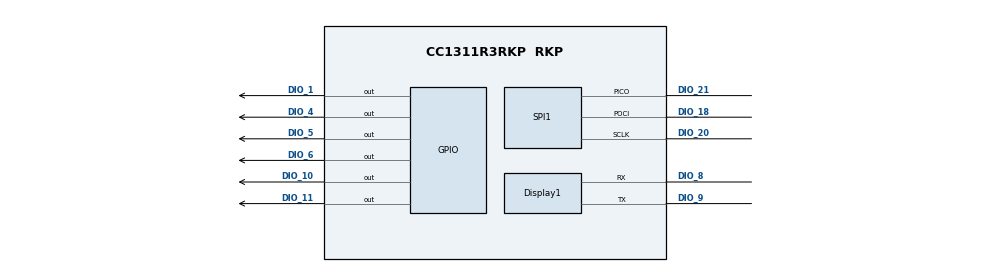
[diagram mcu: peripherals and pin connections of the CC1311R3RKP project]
/**
 * @cliArgs --device "CC1311R3RKP" --part "Default" --package "RKP" --rtos "nortos" --product "simplelink_cc13xx_cc26xx_sdk@8.30.01.01"
 * @versions {"tool":"1.21.1+3772"}
 */

/**
 * Import the modules used in this configuration.
 */
const Display  = scripting.addModule("/ti/display/Display");
const Display1 = Display.addInstance();
const Board    = scripting.addModule("/ti/drivers/Board");
const GPIO     = scripting.addModule("/ti/drivers/GPIO", {}, false);
const GPIO3    = GPIO.addInstance();
const GPIO4    = GPIO.addInstance();
const GPIO5    = GPIO.addInstance();
const GPIO6    = GPIO.addInstance();
const GPIO7    = GPIO.addInstance();
const GPIO8    = GPIO.addInstance();
const NVS      = scripting.addModule("/ti/drivers/NVS");
const NVS1     = NVS.addInstance();
const SPI      = scripting.addModule("/ti/drivers/SPI", {}, false);
const SPI1     = SPI.addInstance();

/**
 * Write custom configuration values to the imported modules.
 */
Display1.$name                   = "CONFIG_DISPLAY_DEBUG";
Display1.baudRate                = 921600;
Display1.uartBufferSize          = 8196;
Display1.uart.$name              = "CONFIG_UART2_DEBUG";
Display1.uart.uart.txPin.$assign = "DIO_9";
Display1.uart.uart.rxPin.$assign = "DIO_8";

Board.generateInitializationFunctions = false;

GPIO3.$name              = "CONFIG_GPIO_EPD_CS";
GPIO3.mode               = "Output";
GPIO3.initialOutputState = "High";
GPIO3.gpioPin.$assign    = "DIO_1";

GPIO4.$name           = "CONFIG_GPIO_EPD_PWR";
GPIO4.mode            = "Output";
GPIO4.gpioPin.$assign = "DIO_4";

GPIO5.$name           = "CONFIG_GPIO_EPD_SDI";
GPIO5.mode            = "Output";
GPIO5.gpioPin.$assign = "DIO_5";

GPIO6.$name           = "CONFIG_GPIO_EPD_CLK";
GPIO6.mode            = "Output";
GPIO6.gpioPin.$assign = "DIO_6";

GPIO7.$name              = "CONFIG_GPIO_EPD_RST";
GPIO7.mode               = "Output";
GPIO7.initialOutputState = "High";
GPIO7.gpioPin.$assign    = "DIO_10";

GPIO8.$name           = "CONFIG_GPIO_EPD_BUSY";
GPIO8.pull            = "Pull Up";
GPIO8.gpioPin.$assign = "DIO_11";

NVS1.nvsType                  = "External";
NVS1.$name                    = "CONFIG_NVS_FLASH";
NVS1.externalFlash.$name      = "ti_drivers_nvs_NVSSPI25X0";
NVS1.externalFlash.regionSize = 0x100000;

const CCFG              = scripting.addModule("/ti/devices/CCFG", {}, false);
CCFG.ccfgTemplate.$name = "ti_devices_CCFG_CCFGCC26XXTemplate0";

const NVSSPI25XDevice                        = scripting.addModule("/ti/drivers/nvs/NVSSPI25XDevice", {}, false);
const NVSSPI25XDevice1                       = NVSSPI25XDevice.addInstance({}, false);
NVSSPI25XDevice1.$name                       = "CONFIG_NVS_SPI_0";
NVS1.externalFlash.spiFlashDevice            = NVSSPI25XDevice1;
NVSSPI25XDevice1.chipSelect.$assign          = "DIO_19";
NVSSPI25XDevice1.chipSelectPinInstance.$name = "CONFIG_GPIO_NVS_FLASH_CS";

NVSSPI25XDevice1.sharedSpiInstance = SPI1;
SPI1.$name                         = "CONFIG_SPI_FLASH";
SPI1.spi.sclkPin.$assign           = "DIO_20";
SPI1.spi.pociPin.$assign           = "DIO_18";
SPI1.spi.picoPin.$assign           = "DIO_21";

/**
 * Pinmux solution for unlocked pins/peripherals. This ensures that minor changes to the automatic solver in a future
 * version of the tool will not impact the pinmux you originally saw.  These lines can be completely deleted in order to
 * re-solve from scratch.
 */
Display1.uart.uart.$suggestSolution    = "UART0";
SPI1.spi.$suggestSolution              = "SSI0";
SPI1.spi.dmaRxChannel.$suggestSolution = "DMA_CH3";
SPI1.spi.dmaTxChannel.$suggestSolution = "DMA_CH4";
